# ESP32S31_RADIO register map
Vendor: Espressif; Series: ESP32-S31; File version: 3.52
Registers are 32-bit, read-write, no defined reset value unless marked. A register's access mark holds for its fields unless they carry their own. Offsets are from the block's base; [hi:lo] are bit positions; {n}, {i} and the like mark numbered series; 'fields as' and 'values as' point back to an identical list; <NAME> marks a mode.

## BLUETOOTH_CONTROLLER_CORE — Bluetooth controller-core register view grouped by runtime responsibility rather than vendor object boundaries. It owns task-side scheduler, sleep-timer, controller initialization, memory-list, scan-snapshot and ISO-coexistence state reached through the 0x20101000 physical block. Interrupt programming, enable/status, acknowledgement and fault diagnostics belong exclusively to BLUETOOTH_INTERRUPT_BANK; the two scheduler words accessed by the hard handler belong exclusively to BLUETOOTH_SCHEDULER_INTERRUPT_RUNTIME.
Base 0x20101000
0x00 SCHEDULER_CONTROL wo — Final hardware command of scheduler run. The complete current run prologue always returns zero after dynamic IRQ preparation and synchronous broker publication, so the following complete leaf writes finite image 1; the same-chip named predecessor identifies the composed operation as r_btdm_sched_run.
  [31:0] COMMAND — Complete final scheduler hardware-run command image.
    on write: 1=RUN (Request scheduler execution after a hardware-list head publication.)
0x04 SCHEDULER_LIFECYCLE_REQUEST wo — The scheduler lifecycle function reached from both BTDM task disable and shutdown writes complete image 1 only after its initial BUSY gate, dynamic interrupt masking, synchronous scheduler-run source disable and command-readiness wait. It then waits for scheduler BUSY to clear. The hardware meaning of this request remains unknown.
  [31:0] IMAGE — Complete lifecycle-request image.
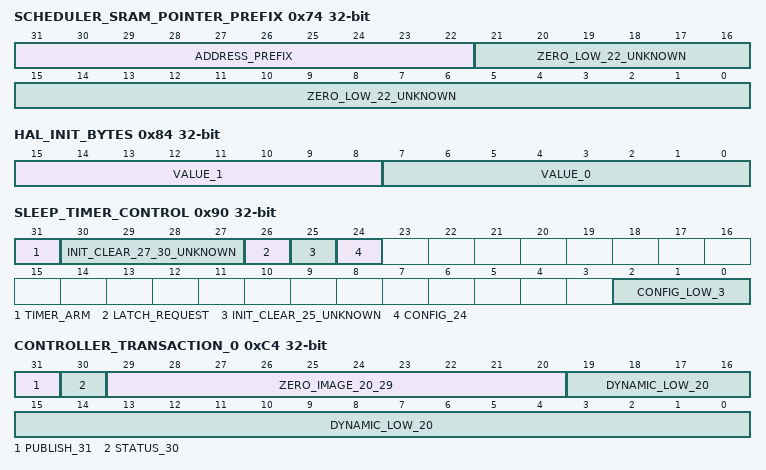
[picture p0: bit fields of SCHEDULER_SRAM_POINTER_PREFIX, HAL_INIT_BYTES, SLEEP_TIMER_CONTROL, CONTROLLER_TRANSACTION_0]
0x74 SCHEDULER_SRAM_POINTER_PREFIX — Hardware initialization publishes bits 22..31 from an SRAM configuration address; scheduler list users OR this prefix with compressed 20-bit pointer values shifted left by two.
  [31:22] ADDRESS_PREFIX
  [21:0] ZERO_LOW_22_UNKNOWN — Full HAL initialization writes zero to the low 22 unassigned positions.
0x80 CONTROLLER_AUXILIARY_POINTER ro — Three observed controller paths read the low twenty bits after consulting SCHEDULER_STATE and reconstruct an SRAM address as 0x2F000000 | (value << 2). The relationship between the two pointer sources remains unknown.
  [19:0] COMPRESSED_SRAM_POINTER
0x84 HAL_INIT_BYTES — Complete BTDM HAL initialization replaces bytes zero and one with two independently runtime-derived values while preserving bits 16..31. Their inner meanings remain unknown.
  [15:8] VALUE_1, [7:0] VALUE_0
0x8C INIT_ZERO_008C wo — One complete controller function writes the finite zero image twice. Its operation meaning remains unknown.
  [31:0] IMAGE
0x90 SLEEP_TIMER_CONTROL — BTDM sleep/wakeup transaction control. Initialization programs bits 0..2 and bit 24; callers set bit 26 and wait for hardware to clear it before reading latched time; the timer-programming path sets bit 31.
  [31] TIMER_ARM
  [30:27] INIT_CLEAR_27_30_UNKNOWN — HAL initialization clears these unassigned positions together with the complete high-byte reset.
  [26] LATCH_REQUEST
  [25] INIT_CLEAR_25_UNKNOWN — HAL initialization clears this unassigned position together with the complete high-byte reset.
  [24] CONFIG_24
  [2:0] CONFIG_LOW_3
0x94 SLEEP_TIMER_VALUE_0 — First runtime-derived complete word published immediately before SLEEP_TIMER_CONTROL.TIMER_ARM. Inner meaning remains unknown.
  [31:0] IMAGE
0x98 SLEEP_TIMER_VALUE_1 — Second runtime-derived complete word published immediately before SLEEP_TIMER_CONTROL.TIMER_ARM. Inner meaning remains unknown.
  [31:0] IMAGE
0x9C SLEEP_TIMER_VALUE_2 — Third runtime-derived complete word published immediately before SLEEP_TIMER_CONTROL.TIMER_ARM. Inner meaning remains unknown.
  [31:0] IMAGE
0xAC SLEEP_TIMER_LATCHED_TIME_0 ro — First word of the three-word sleep-timer snapshot read after software requests a latch and hardware clears SLEEP_TIMER_CONTROL.LATCH_REQUEST.
  [31:0] IMAGE
0xB0 SLEEP_TIMER_LATCHED_TIME_1 ro — Second word of the same three-word sleep-timer snapshot. Its inner counter or window meaning remains unknown.
  [31:0] IMAGE
0xB4 SLEEP_TIMER_LATCHED_TIME_2 ro — Third word of the same three-word sleep-timer snapshot. Its inner counter or window meaning remains unknown.
  [31:0] IMAGE
0xB8 INIT_ZERO_00B8 wo — One complete controller function writes the finite zero image twice. Its operation meaning remains unknown.
  [31:0] IMAGE
0xC4 CONTROLLER_TRANSACTION_0 — First positional controller transaction word. The observed instruction sequence publishes bit 31 together with a dynamic low-twenty-bit value, waits for bit 30, then republishes while bit 31 remains clear. The hardware operation remains unknown.
  [31] PUBLISH_31
  [30] STATUS_30
  [29:20] ZERO_IMAGE_20_29 — Every observed complete publication writes these positions as zero; no hardware-field semantics are assigned.
  [19:0] DYNAMIC_LOW_20
0xC8 SCHEDULER_LIST_POINTER_0 — First 20-bit scheduler-list pointer; software reconstructs SRAM address as SCHEDULER_SRAM_POINTER_PREFIX | (value << 2).
  [19:0] COMPRESSED_SRAM_POINTER
0xCC SCHEDULER_LIST_POINTER_1 — Second 20-bit scheduler-list pointer; software reconstructs SRAM address as SCHEDULER_SRAM_POINTER_PREFIX | (value << 2).
  [19:0] COMPRESSED_SRAM_POINTER
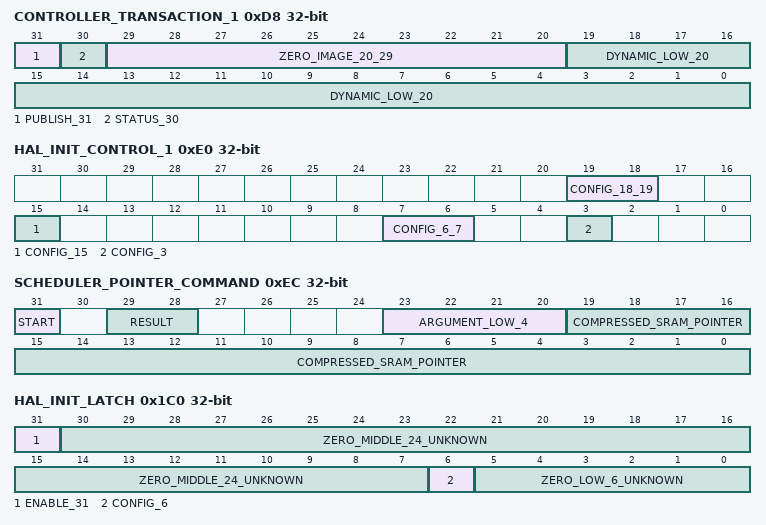
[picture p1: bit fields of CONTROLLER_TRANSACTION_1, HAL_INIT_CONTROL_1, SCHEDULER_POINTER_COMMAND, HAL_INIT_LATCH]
0xD8 CONTROLLER_TRANSACTION_1 — Second positional controller transaction word. Observed instruction sequences publish bit 31 with either a dynamic low-twenty-bit value or zero, wait for bit 30, then republish while bit 31 remains clear. The hardware operation remains unknown.
  fields as CONTROLLER_TRANSACTION_0
0xDC HAL_INIT_CONTROL_0 — BTDM HAL initialization sets bit 31 through a fresh-read RMW. The control meaning remains unknown.
  [31] ENABLE_31
0xE0 HAL_INIT_CONTROL_1 — BTDM HAL initialization replaces and sets the six independently observed positions 3, 6, 7, 15, 18 and 19. Positional groups preserve the exact masks without assigning hardware meaning.
  [19:18] CONFIG_18_19, [15] CONFIG_15, [7:6] CONFIG_6_7, [3] CONFIG_3
0xEC SCHEDULER_POINTER_COMMAND — Pointer command transaction: compressed pointer in bits 0..19, four-bit argument in bits 20..23 and START in bit 31; completion returns a two-bit result in bits 28..29.
  [31] START, [29:28] RESULT, [23:20] ARGUMENT_LOW_4, [19:0] COMPRESSED_SRAM_POINTER
0x1C0 HAL_INIT_LATCH — BTDM HAL initialization writes the finite complete image 0x40 and then sets bit 31 through a fresh-read RMW. Inner semantics remain unknown.
  [31] ENABLE_31
  [30:7] ZERO_MIDDLE_24_UNKNOWN — The initial complete HAL write clears these unassigned positions.
  [6] CONFIG_6
  [5:0] ZERO_LOW_6_UNKNOWN — The initial complete HAL write clears these unassigned positions.
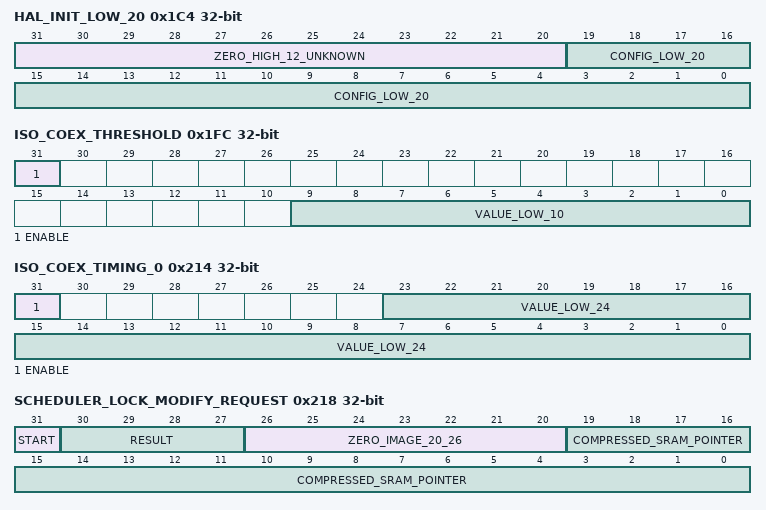
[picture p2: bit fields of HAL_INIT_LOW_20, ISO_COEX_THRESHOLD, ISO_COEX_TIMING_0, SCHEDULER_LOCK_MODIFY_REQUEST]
0x1C4 HAL_INIT_LOW_20 wo — BTDM HAL initialization writes the finite complete image 0x000FFFFF. Inner semantics remain unknown.
  [31:20] ZERO_HIGH_12_UNKNOWN — The complete HAL write clears the unassigned high positions.
  [19:0] CONFIG_LOW_20
0x1F0 PHY_INIT_VALUE_01F0 wo — Complete BLE PHY initialization writes the finite whole-word image 0x55. The destination's inner hardware meaning remains unknown.
  [31:0] IMAGE
0x1F4 ISO_COEX_ENABLE — ISO coexistence initialization sets bit 0; deinitialization clears it.
  [0] ENABLE
0x1F8 ISO_COEX_CONTROL_0 — ISO coexistence initialization sets bit 0. Inner control semantics remain unknown.
  [0] ENABLE_0
0x1FC ISO_COEX_THRESHOLD — ISO coexistence initialization writes low ten-bit value 100 and then sets bit 31.
  [31] ENABLE, [9:0] VALUE_LOW_10
0x200 ISO_COEX_CONTROL_1 — ISO coexistence initialization sets bit 0. Inner control semantics remain unknown.
  [0] ENABLE_0
0x204 OPERATIONAL_CONTROL_0204 — Complete operational functions independently set and clear bit zero through fresh-read RMW operations.
  [0] CONTROL_0
0x208 OPERATIONAL_STATUS_0208 ro — Two complete operational functions consume bit zero as the second wait predicate after setting OPERATIONAL_CONTROL_0204 bit zero. They continue waiting while this bit is one and SCHEDULER_STATE.BUSY is set, then clear the control bit. The remaining bits and the hardware meaning of bit zero are unknown.
  [0] STATUS_0
0x20C ISO_COEX_STATE_0 — ISO coexistence initialization and deinitialization write the complete zero image.
  [31:0] IMAGE
0x210 ISO_COEX_STATE_1 — ISO coexistence initialization and deinitialization write the complete zero image.
  [31:0] IMAGE
0x214 ISO_COEX_TIMING_0 — ISO coexistence initialization publishes a runtime-derived low 24-bit value and then sets bit 31.
  [31] ENABLE, [23:0] VALUE_LOW_24
0x218 SCHEDULER_LOCK_MODIFY_REQUEST — The scheduler insert-with-lock-modify path publishes START with a compressed SRAM pointer. Before and after publication it may progress whenever either START or SCHEDULER_STATE.BUSY is clear. When that publication wait ends it reports zero when BUSY is clear, otherwise the positional four-bit RESULT image returned in bits 30:27; this is not radio-item completion.
  [31] START, [30:27] RESULT, [26:20] ZERO_IMAGE_20_26, [19:0] COMPRESSED_SRAM_POINTER
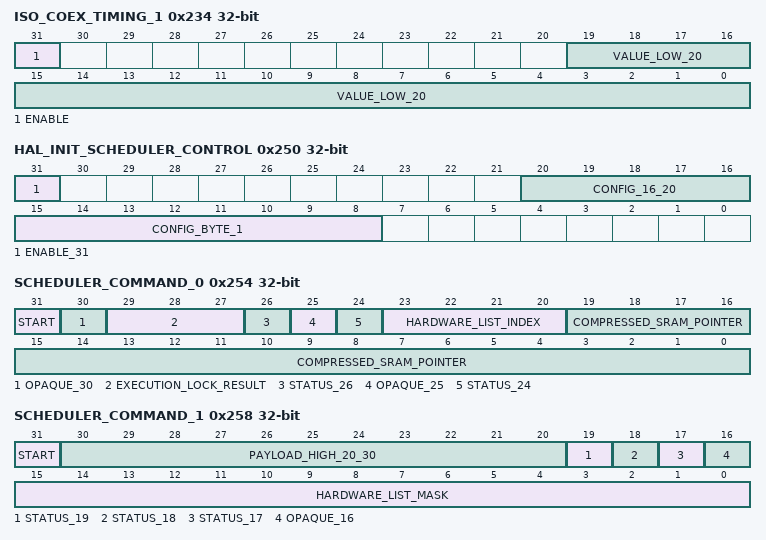
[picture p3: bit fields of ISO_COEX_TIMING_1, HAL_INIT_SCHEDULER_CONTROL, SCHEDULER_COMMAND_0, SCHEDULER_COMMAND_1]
0x234 ISO_COEX_TIMING_1 — ISO coexistence initialization publishes a runtime-derived low 20-bit value and then sets bit 31.
  [31] ENABLE, [19:0] VALUE_LOW_20
0x244 PHY_INIT_ZERO_0244 wo — Complete BLE PHY initialization writes the finite whole-word zero image. Inner hardware meaning remains unknown.
  [31:0] IMAGE
0x248 PHY_INIT_VALUE_0248 wo — Complete BLE PHY initialization writes the finite whole-word image 0x00000FFF. Inner hardware meaning remains unknown.
  [31:0] IMAGE
0x24C PHY_INIT_DYNAMIC_IMAGE_024C wo — Complete BLE PHY initialization writes a runtime-derived complete image formed from a linked global address plus 0x40. The destination's inner hardware meaning remains unknown.
  [31:0] IMAGE
0x250 HAL_INIT_SCHEDULER_CONTROL — BTDM HAL initialization configures byte one to 0x20, bits 16..20 to 0x10 and sets bit 31. Names remain positional because the controller meaning is not recovered.
  [31] ENABLE_31, [20:16] CONFIG_16_20, [15:8] CONFIG_BYTE_1
0x254 SCHEDULER_COMMAND_0 — First scheduler command/status transaction. The insertion execution-lock request publishes a compressed item pointer, hardware-list index and START; its finite wait observes positional status 24 and a three-bit result. Other complete paths inspect positional status 26.
  [31] START, [30] OPAQUE_30, [29:27] EXECUTION_LOCK_RESULT, [26] STATUS_26, [25] OPAQUE_25, [24] STATUS_24, [23:20] HARDWARE_LIST_INDEX, [19:0] COMPRESSED_SRAM_POINTER
0x258 SCHEDULER_COMMAND_1 — Second scheduler command/status transaction. The insertion execution-modify request publishes a sixteen-list selection mask and START; its finite wait observes positional status bits 17 and 19. Other complete paths inspect positional status 18.
  [31] START, [30:20] PAYLOAD_HIGH_20_30, [19] STATUS_19, [18] STATUS_18, [17] STATUS_17, [16] OPAQUE_16, [15:0] HARDWARE_LIST_MASK
0x25C SCHEDULER_FINISHED_LIST_STATUS ro — The scheduler worker reads the low 16 bits as the finished hardware-list mask, copies that image to SCHEDULER_FINISHED_LIST_REPORT and dispatches the mask to the BLE finished-item selector.
  [15:0] FINISHED_LIST_MASK
0x260 SCHEDULER_FINISHED_LIST_REPORT — Before software finished-item dispatch, the scheduler worker writes the observed 16-bit SCHEDULER_FINISHED_LIST_STATUS mask as a complete zero-high image. The hardware effect of this report remains positional; other reviewed paths can clear the complete word.
  [15:0] FINISHED_LIST_MASK
0x27C HAL_INIT_LOW_HALF — BTDM HAL initialization first clears and then sets all bits in the low halfword through two fresh-read RMW operations. Inner semantics remain unknown.
  [15:0] CONFIG_LOW_16
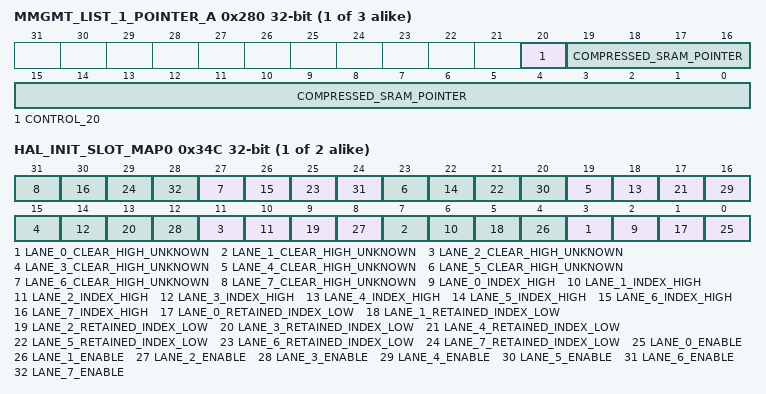
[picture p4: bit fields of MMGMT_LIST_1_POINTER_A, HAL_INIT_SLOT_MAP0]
{0x278+8i} MMGMT_LIST_{i}_POINTER_A (i=1..3) — Selector {i} pointer A; memory-management paths also independently consume or clear control bit 20.
  [20] CONTROL_20, [19:0] COMPRESSED_SRAM_POINTER
{0x27C+8i} MMGMT_LIST_{i}_POINTER_B (i=1..3) — Selector {i} pointer B.
  [19:0] COMPRESSED_SRAM_POINTER
0x2A0 SCAN_HW_SNAPSHOT ro — BLE scan code reads this complete word twice until stable, converts it and stores the result in scan state. Inner hardware encoding remains unknown.
  [31:0] IMAGE
0x324 OPERATIONAL_STATUS_0324 ro — Two complete operational functions read the complete word; its inner encoding remains unknown.
  [31:0] IMAGE
{0x34C+4i} HAL_INIT_SLOT_MAP{i} (i=0..1) — The adjacent words at 0x2010134c and 0x20101350 each hold eight independently initialized four-bit lanes. For every lane, the complete BTDM HAL loop first clears bits 3:2, then sets bit 0, conditionally sets but never clears bit 1, and publishes the global-index high bit into bit 2. The hardware meaning of the words and values remains unknown.
  [4n+3] LANE_{n}_CLEAR_HIGH_UNKNOWN (n=0..7), [4n+2] LANE_{n}_INDEX_HIGH (n=0..7), [4n+1] LANE_{n}_RETAINED_INDEX_LOW (n=0..7), [4n] LANE_{n}_ENABLE (n=0..7)
0x36C OPERATIONAL_WORD_036C — Scheduler operational word shared by several controller paths. The scheduler insert-with-lock-modify path clears, then publishes, the zero-based hardware-list index through two distinct fresh-read field updates before publishing SCHEDULER_LOCK_MODIFY_REQUEST. Other fields remain unassigned.
  [3:0] LOCK_MODIFY_HARDWARE_LIST_INDEX — Zero-based hardware-list index cleared and then published by scheduler insert-with-lock-modify.
